VERSION "2018/11/09 Version 1.06"

NS_ :

BS_:

BU_: MCP iXS iXT

BO_ 272 MCP_STEER_ANGLE_COMMAND: 2 MCP
 SG_ SACMD : 0|16@2- (0.1,0) [-720|720] "degree" iXS

BO_ 529 MCP_STEER_ANGLE_FEEDBACK: 2 iXS
 SG_ SAFB : 0|16@2- (0.1,0) [-720|720] "degree" MCP

BO_ 288 MCP_FRONT_BRAKE_COMMAND: 3 MCP
 SG_ FWBOO : 16|1@1+ (1,0) [0|0] "ON/OFF" iXB
 SG_ FWBPVV : 0|12@1+ (0.0012210012210012,0) [0|0] "N/A" iXB

BO_ 289 MCP_REAR_BRAKE_COMMAND: 3 MCP
 SG_ RWBOO : 16|1@1+ (1,0) [0|0] "ON/OFF" iXB
 SG_ RWBPVV : 0|12@1+ (0.0012210012210012,0) [0|0] "N/A" iXB

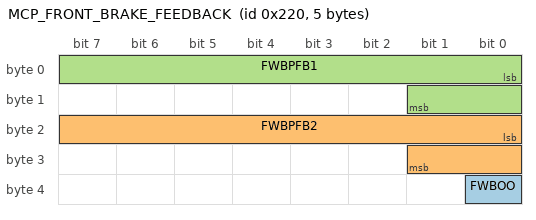
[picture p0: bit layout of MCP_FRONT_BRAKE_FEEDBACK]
BO_ 544 MCP_FRONT_BRAKE_FEEDBACK: 5 iXB
 SG_ FWBOO : 32|1@1+ (1,0) [0|0] "ON/OFF" MCP
 SG_ FWBPFB2 : 16|10@1+ (0.004887585532747,0) [0|0] "N/A" MCP
 SG_ FWBPFB1 : 0|10@1+ (0.004887585532747,0) [0|0] "N/A" MCP

BO_ 545 MCP_REAR_BRAKE_FEEDBACK: 3 iXB
 SG_ RWBOO : 16|1@1+ (1,0) [0|0] "ON/OFF" MCP
 SG_ RWBPFB : 0|10@1+ (0.004887585532747,0) [0|0] "N/A" MCP

BO_ 304 MCP_THROTTLE_COMMAND: 2 MCP
 SG_ THRCMD : 0|16@1+ (0.0001,0) [0|0] "Volt" iXT

BO_ 560 MCP_THROTTLE_FEEDBACK: 3 iXT
 SG_ THR_STATUS : 16|1@1+ (1,0) [0|0] "" MCP
 SG_ THR_VCU : 0|10@1+ (0.0048828125,0) [0|0] "Volt" MCP

BO_ 561 MCP_THROTTLE_FEEDBACK1: 2 iXT
 SG_ THR_PEDAL : 0|10@1+ (0.0048828125,0) [0|0] "Volt" MCP

BO_ 2000 MCP_EMERGENCY_ONOFF_COMMAND: 1 OCC
 SG_ EMERGENCYONOFF : 0|1@2+ (1,0) [0|0] "N/A" MCP

BO_ 2001 MCP_STATE_MACHINE_STATUS_REPORT: 1 MCP
 SG_ STATEMACHINE : 0|8@2+ (1,0) [0|0] "N/A" OCC

BA_DEF_ "BusType" STRING ;
BA_DEF_DEF_ "BusType" "";
BA_ "BusType" "CAN";
